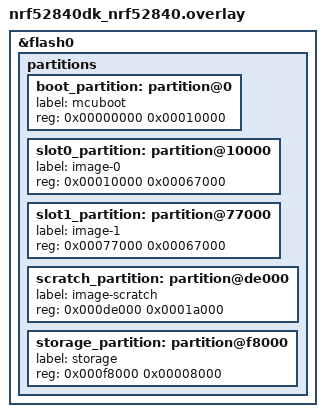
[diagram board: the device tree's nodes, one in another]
/delete-node/ &boot_partition;
/delete-node/ &slot0_partition;
/delete-node/ &slot1_partition;
/delete-node/ &scratch_partition;
/delete-node/ &storage_partition;

&flash0 {
	partitions {
		boot_partition: partition@0 {
			label = "mcuboot";
			reg = <0x00000000 0x00010000>;
		};
		slot0_partition: partition@10000 {
			label = "image-0";
			reg = <0x00010000 0x00067000>;
		};
		slot1_partition: partition@77000 {
			label = "image-1";
			reg = <0x00077000 0x00067000>;
		};
		scratch_partition: partition@de000 {
			label = "image-scratch";
			reg = <0x000de000 0x0001a000>;
		};
		storage_partition: partition@f8000 {
			label = "storage";
			reg = <0x000f8000 0x00008000>;
		};
	};
};
